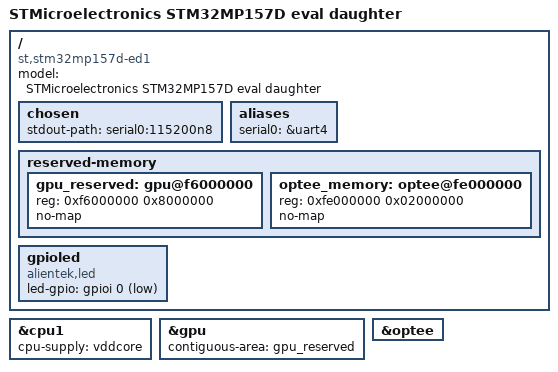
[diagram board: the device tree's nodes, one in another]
// SPDX-License-Identifier: (GPL-2.0+ OR BSD-3-Clause)
/*
 * Copyright (C) STMicroelectronics 2019 - All Rights Reserved
 * Author: Alexandre Torgue <alexandre.torgue@st.com> for STMicroelectronics.
 */
/dts-v1/;

#include "stm32mp157.dtsi"
#include "stm32mp15xd.dtsi"
#include "stm32mp15-pinctrl.dtsi"
#include "stm32mp15xxaa-pinctrl.dtsi"
#include "stm32mp157-m4-srm.dtsi"
#include "stm32mp157-m4-srm-pinctrl.dtsi"
#include "stm32mp157d-atk.dtsi"

/ {
	model = "STMicroelectronics STM32MP157D eval daughter";
	compatible = "st,stm32mp157d-ed1", "st,stm32mp157";

	chosen {
		stdout-path = "serial0:115200n8";
	};

	aliases {
		serial0 = &uart4;
	};

	reserved-memory {
		gpu_reserved: gpu@f6000000 {
			reg = <0xf6000000 0x8000000>;
			no-map;
		};

		optee_memory: optee@fe000000 {
			reg = <0xfe000000 0x02000000>;
			no-map;
		};
	};
		
	/**************************05_gpioled dts start******************************************************
	教程		:【正点原子】STM32MP1嵌入式Linux驱动开发指南V2.1.pdf	【章节】25.4.1	
	文件名		: 05_gpioled
	作者+日期  	: zhong 2024-0113
	描述	   	: 使用pinctrl+gpio配置led的DTS文件
	使用方法	:make dtbs	//见"dts使用教程.md"
				cp arch/arm/boot/dts/stm32mp157d-atk.dtb ~/linux/tftpboot/ -f	*/
	// 以下是dts更改部分：
	gpioled{
		compatible = "alientek,led";
		status = "okay";
		led-gpio = <&gpioi 0 GPIO_ACTIVE_LOW>;	//GPIO的PI0，低电平有效
	};
	/**************************05_gpioled dts end*********************************************************/

};

&cpu1{
	cpu-supply = <&vddcore>;
};

&gpu {
	contiguous-area = <&gpu_reserved>;
	status = "okay";
};

&optee {
	status = "okay";
};
